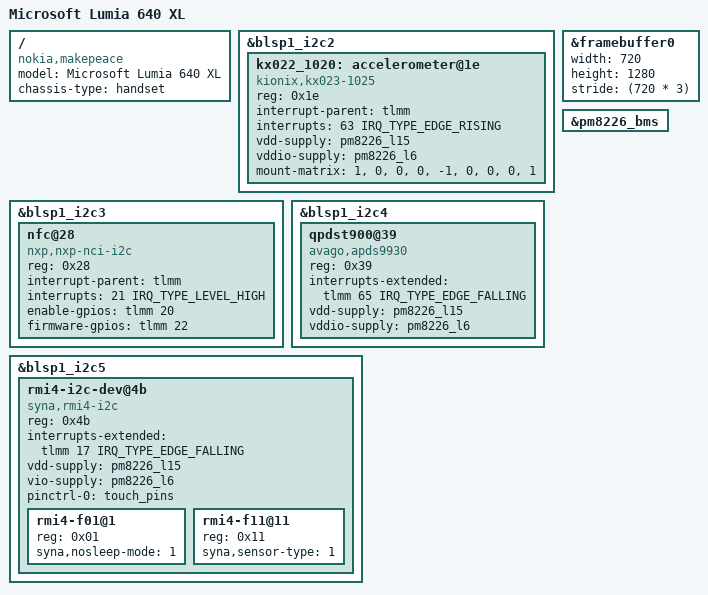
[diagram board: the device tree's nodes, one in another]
// SPDX-License-Identifier: BSD-3-Clause
/*
 * Copyright (c) 2022, Jack Matthews <jm5112356@gmail.com>
 * Copyright (c) 2022, Ivaylo Ivanov <ivo.ivanov.ivanov1@gmail.com>
 * Copyright (c) 2022, Dominik Kobinski <dominikkobinski314@gmail.com>
 * Copyright (c) 2022, Rayyan Ansari <rayyan@ansari.sh>
 */

/dts-v1/;

#include "qcom-msm8226-nokia-common.dtsi"

/ {
	model = "Microsoft Lumia 640 XL";
	compatible = "nokia,makepeace","qcom,msm8226";
	chassis-type = "handset";
};

&blsp1_i2c2 {
	status = "okay";

	kx022_1020: accelerometer@1e {
		/*
		 * This is actually the Kionix KX022-1020, but the KX023-1025 driver
		 * seems to work fine for now.
		 */
		compatible = "kionix,kx023-1025";
		reg = <0x1e>;

		interrupt-parent = <&tlmm>;
		interrupts = <63 IRQ_TYPE_EDGE_RISING>;

		vdd-supply = <&pm8226_l15>;
		vddio-supply = <&pm8226_l6>;

		mount-matrix =  "1",  "0",  "0",
						"0", "-1",  "0",
						"0",  "0",  "1";
	};
};

&blsp1_i2c3 {
	status = "okay";

	nfc@28 {
		compatible = "nxp,nxp-nci-i2c";
		reg = <0x28>;

		interrupt-parent = <&tlmm>;
		interrupts = <21 IRQ_TYPE_LEVEL_HIGH>;

		enable-gpios = <&tlmm 20 GPIO_ACTIVE_HIGH>;
		firmware-gpios = <&tlmm 22 GPIO_ACTIVE_HIGH>;
	};
};

&blsp1_i2c4 {
	status = "okay";

	qpdst900@39 {
		compatible = "avago,apds9930";
		reg = <0x39>;

		interrupts-extended = <&tlmm 65 IRQ_TYPE_EDGE_FALLING>;

		vdd-supply = <&pm8226_l15>;
		vddio-supply = <&pm8226_l6>;

	};
};

&blsp1_i2c5 {
	status = "okay";

	rmi4-i2c-dev@4b {
		compatible = "syna,rmi4-i2c";
		reg = <0x4b>;
		#address-cells = <1>;
		#size-cells = <0>;

		interrupts-extended = <&tlmm 17 IRQ_TYPE_EDGE_FALLING>;
		vdd-supply = <&pm8226_l15>;
		vio-supply = <&pm8226_l6>;

		pinctrl-names = "default";
		pinctrl-0 = <&touch_pins>;

		rmi4-f01@1 {
			reg = <0x01>;
			syna,nosleep-mode = <1>;
		};

		rmi4-f11@11 {
			reg = <0x11>;
			syna,sensor-type = <1>;
		};
	};
};

&framebuffer0 {
	width = <720>;
	height = <1280>;
	stride = <(720 * 3)>;
};


&pm8226_bms {
	status = "okay";
};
